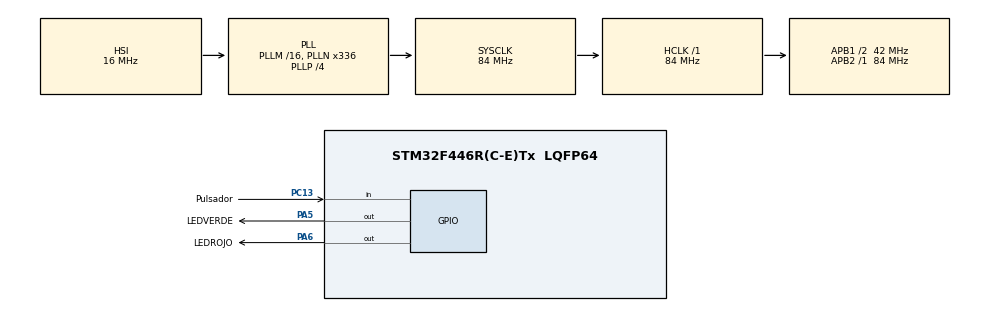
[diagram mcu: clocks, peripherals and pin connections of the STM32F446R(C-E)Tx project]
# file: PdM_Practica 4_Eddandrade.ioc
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Mcu.Family=STM32F4
Mcu.Name=STM32F446R(C-E)Tx
Mcu.Package=LQFP64
NVIC.PriorityGroup=NVIC_PRIORITYGROUP_0
PA13.GPIO_Label=TMS
PA13.Mode=Serial_Wire
PA13.Signal=SYS_JTMS-SWDIO
PA14.GPIO_Label=TCK
PA14.Mode=Serial_Wire
PA14.Signal=SYS_JTCK-SWCLK
PA5.GPIO_Label=LEDVERDE
PA5.Signal=GPIO_Output
PA6.GPIO_Label=LEDROJO
PA6.Signal=GPIO_Output
PB3.GPIO_Label=SWO
PB3.Signal=SYS_JTDO-SWO
PC13.GPIO_Label=Pulsador
PC13.GPIO_Mode=GPIO_MODE_INPUT
PC13.GPIO_PuPd=GPIO_NOPULL
PC13.Signal=GPIO_Input
PC14-OSC32_IN.Mode=LSE-External-Oscillator
PC14-OSC32_IN.Signal=RCC_OSC32_IN
PC15-OSC32_OUT.Mode=LSE-External-Oscillator
PC15-OSC32_OUT.Signal=RCC_OSC32_OUT
PH0-OSC_IN.Mode=HSE-External-Oscillator
PH0-OSC_IN.Signal=RCC_OSC_IN
PH1-OSC_OUT.Mode=HSE-External-Oscillator
PH1-OSC_OUT.Signal=RCC_OSC_OUT
ProjectManager.HeapSize=0x200
ProjectManager.StackSize=0x400
ProjectManager.TargetToolchain=STM32CubeIDE
RCC.48MHZClocksFreq_Value=84000000
RCC.AHBFreq_Value=84000000
RCC.APB1CLKDivider=RCC_HCLK_DIV2
RCC.APB1Freq_Value=42000000
RCC.APB1TimFreq_Value=84000000
RCC.APB2Freq_Value=84000000
RCC.APB2TimFreq_Value=84000000
RCC.CortexFreq_Value=84000000
RCC.FLatency-AdvancedSettings=FLASH_LATENCY_2
RCC.HCLKFreq_Value=84000000
RCC.HSE_VALUE=8000000
RCC.HSI_VALUE=16000000
RCC.PLLN=336
RCC.PLLP=RCC_PLLP_DIV4
RCC.SYSCLKFreq_VALUE=84000000
RCC.SYSCLKSource=RCC_SYSCLKSOURCE_PLLCLK
RCC.USBFreq_Value=168000000
RCC.VCOOutputFreq_Value=336000000
board=NUCLEO-F446RE

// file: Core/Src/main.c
/* USER CODE BEGIN Header */
/**
  ******************************************************************************
  * @file           : main.c
  * @brief          : Main program body
  ******************************************************************************
  * @attention
  *
  * Copyright (c) 2023 STMicroelectronics.
  * All rights reserved.
  *
  * This software is licensed under terms that can be found in the LICENSE file
  * in the root directory of this software component.
  * If no LICENSE file comes with this software, it is provided AS-IS.
  *
  ******************************************************************************
  */
/* USER CODE END Header */
#include "main.h"
#include "gpio.h"

/* USER CODE BEGIN PD */
#define TRUE 1
#define FALSE 0
#define DELAY1 100
#define DELAY2 500
//#define DELAY3 1000
/* USER CODE END PD */

void SystemClock_Config(void);
/* USER CODE BEGIN PFP */
void buttonPressed();

void buttonReleased();
/* USER CODE END PFP */

int main(void)
{
  /* USER CODE BEGIN 1 */
	delay_t Delay1, Delay2;
	typedef enum
	{ DELAY_1, DELAY_2} switchkey;

	switchkey Switch_Key=DELAY_1;

  /* USER CODE END 1 */

  /* MCU Configuration--------------------------------------------------------*/

  /* Reset of all peripherals, Initializes the Flash interface and the Systick. */
  HAL_Init();

  /* USER CODE BEGIN Init */
  debounceFSM_init();
  delayInit(&Delay1,DELAY1);
  delayInit(&Delay2,DELAY2);

  /* USER CODE END Init */

  /* Configure the system clock */
  SystemClock_Config();

  /* Initialize all configured peripherals */
  MX_GPIO_Init();
  /* USER CODE BEGIN 2 */
  MX_GPIO_Init(); //inicia el LEDVERDE

  /* USER CODE END 2 */

  /* Infinite loop */
  while (1)
  {

    /* USER CODE BEGIN 3 */

	debounceFSM_update();
	bool_t Key=readKey();

	if (Key==TRUE)
	{
		switch (Switch_Key)
		{
		       case DELAY_1:

					if (delayRead(&Delay1) == true)	HAL_GPIO_TogglePin(LEDVERDE_GPIO_Port,LEDVERDE_Pin);
					Switch_Key=DELAY_2;
					break;

			   case DELAY_2:

					if (delayRead(&Delay2) == true)	HAL_GPIO_TogglePin(LEDVERDE_GPIO_Port,LEDVERDE_Pin);
					Switch_Key=DELAY_1;
				    break;
		}

	}
	/*
	if (delayRead(&Delay1) == true && delayRead(&Delay2)!= true && delayRead(&Delay3)!= true) { // El retardo se ha cumplido, encender o apagar LED1
		  HAL_GPIO_TogglePin(GPIOA, LEDVERDE_Pin);

	        }
	        if (delayRead(&Delay2) == true && delayRead(&Delay1)!= true && delayRead(&Delay3)!= true) { // El retardo se ha cumplido, encender o apagar LED2
	      	  HAL_GPIO_TogglePin(GPIOA, LEDVERDE_Pin);
	        }
	        /*if (delayRead(&Delay3) == true && delayRead(&Delay1)!= true && delayRead(&Delay2)!= true) { // El retardo se ha cumplido, encender o apagar LED3
	      	  HAL_GPIO_TogglePin(GPIOA, LEDVERDE_Pin);
	        }*/

  }
  /* USER CODE END 3 */
}

void SystemClock_Config(void)
{
  RCC_OscInitTypeDef RCC_OscInitStruct = {0};
  RCC_ClkInitTypeDef RCC_ClkInitStruct = {0};

  /** Configure the main internal regulator output voltage
  */
  __HAL_RCC_PWR_CLK_ENABLE();
  __HAL_PWR_VOLTAGESCALING_CONFIG(PWR_REGULATOR_VOLTAGE_SCALE3);

  /** Initializes the RCC Oscillators according to the specified parameters
  * in the RCC_OscInitTypeDef structure.
  */
  RCC_OscInitStruct.OscillatorType = RCC_OSCILLATORTYPE_HSI;
  RCC_OscInitStruct.HSIState = RCC_HSI_ON;
  RCC_OscInitStruct.HSICalibrationValue = RCC_HSICALIBRATION_DEFAULT;
  RCC_OscInitStruct.PLL.PLLState = RCC_PLL_ON;
  RCC_OscInitStruct.PLL.PLLSource = RCC_PLLSOURCE_HSI;
  RCC_OscInitStruct.PLL.PLLM = 16;
  RCC_OscInitStruct.PLL.PLLN = 336;
  RCC_OscInitStruct.PLL.PLLP = RCC_PLLP_DIV4;
  RCC_OscInitStruct.PLL.PLLQ = 2;
  RCC_OscInitStruct.PLL.PLLR = 2;
  if (HAL_RCC_OscConfig(&RCC_OscInitStruct) != HAL_OK)
  {
    Error_Handler();
  }

  /** Initializes the CPU, AHB and APB buses clocks
  */
  RCC_ClkInitStruct.ClockType = RCC_CLOCKTYPE_HCLK|RCC_CLOCKTYPE_SYSCLK
                              |RCC_CLOCKTYPE_PCLK1|RCC_CLOCKTYPE_PCLK2;
  RCC_ClkInitStruct.SYSCLKSource = RCC_SYSCLKSOURCE_PLLCLK;
  RCC_ClkInitStruct.AHBCLKDivider = RCC_SYSCLK_DIV1;
  RCC_ClkInitStruct.APB1CLKDivider = RCC_HCLK_DIV2;
  RCC_ClkInitStruct.APB2CLKDivider = RCC_HCLK_DIV1;

  if (HAL_RCC_ClockConfig(&RCC_ClkInitStruct, FLASH_LATENCY_2) != HAL_OK)
  {
    Error_Handler();
  }
}

/* USER CODE BEGIN 4 */
void buttonPressed()
{
	//HAL_GPIO_TogglePin(LEDVERDE_GPIO_Port,LEDVERDE_Pin);
	}

void buttonReleased()
{
	//HAL_GPIO_TogglePin(LEDROJO_GPIO_Port,LEDROJO_Pin);

	}

/* USER CODE END 4 */

void Error_Handler(void)
{
  /* USER CODE BEGIN Error_Handler_Debug */
	HAL_GPIO_TogglePin(LEDROJO_GPIO_Port,LEDROJO_Pin);
  /* User can add his own implementation to report the HAL error return state */
  __disable_irq();
  while (1)
  {
  }
  /* USER CODE END Error_Handler_Debug */
}
